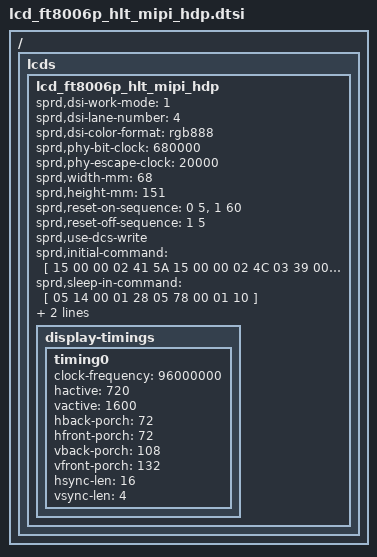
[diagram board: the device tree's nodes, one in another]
/ { lcds {
	lcd_ft8006p_hlt_mipi_hdp: lcd_ft8006p_hlt_mipi_hdp {

		sprd,dsi-work-mode = <1>; /* video burst mode*/
		sprd,dsi-lane-number = <4>;
		sprd,dsi-color-format = "rgb888";

		sprd,phy-bit-clock = <680000>;	/* kbps */
		sprd,phy-escape-clock = <20000>;/* kHz */

		sprd,width-mm = <68>;
		sprd,height-mm = <151>;

		sprd,reset-on-sequence = <0 5>, <1 60>;
		sprd,reset-off-sequence = <1 5>;

		sprd,use-dcs-write;

		sprd,initial-command = [
			/*------------  Display Initial Code Setting  ------------------------*/
			15 00 00 02 41 5A

			15 00 00 02 4C 03

			39 00 00 03 41 5A 03
			39 00 00 03 80 A9 00

			/*----------------------LCD initial code start----------------------*/
			/* Blank 9 */
			39 00 00 03 41 5A 09
			39 00 00 06 80 64 00 64 00 00
			/* Blank 10 */
			39 00 00 03 41 5A 0A
			39 00 00 11 80 A5 15 A5 AA A5 88 42 C8 8C 03 07 05 39 61 32 5A
			39 00 00 11 90 0C 0F 22 00 2A 18 64 00 88 03 03 EE EE 00 3F 2A
			39 00 00 11 A0 00 30 02 32 11 0D 60 01 FF FF 03 40 42 0F 94 11
			39 00 00 11 B0 E8 03 00 00 11 0D 60 00 FF FF 03 FF 34 0C 0F 0E
			39 00 00 0b C0 1F 03 00 08 20 34 00 00 00 00
			/* Blank 11 */
			39 00 00 03 41 5A 0B
			39 00 00 11 80 FF BE E6 00 00 04 10 1D 26 30 40 4D 51 5E 63 7A
			39 00 00 11 90 86 70 6F 62 5A 4C 3D 33 29 18 06 01 00 04 10 1D
			39 00 00 11 A0 26 30 40 4D 51 5E 63 7A 86 70 6F 62 5A 4C 3D 33
			39 00 00 06 B0 29 18 06 01 00
			/* Blank 12 */
			39 00 00 03 41 5A 0C
			39 00 00 11 80 00 00 20 42 00 00 80 05 54 00 00 00 20 42 00 00
			39 00 00 03 90 80 05
			/* Blank 13 */
			39 00 00 03 41 5A 0D
			39 00 00 11 80 7A D0 02 40 06 D7 00 FA 00 0A 0A 0A 0A 00 01 03
			39 00 00 11 90 00 00 00 00 AC A2 2A 00 00 00 AC A2 2A 57 31 00
			39 00 00 11 A0 00 00 00 00 00 AC A2 2A AA C2 2A AC A2 2A AA C2
			39 00 00 07 B0 2A 00 00 00 AA 52
			/* Blank 14 */
			39 00 00 03 41 5A 0E
			39 00 00 0d 80 F0 B1 71 EF 4B 20 37 0F AA AA 00 00
			/* Blank 15 */
			39 00 00 03 41 5A 0F
			39 00 00 0c 80 FF 00 55 55 23 88 88 1C 00 5A 5A
			/* Blank 16 */
			39 00 00 03 41 5A 10
			39 00 00 11 80 B5 45 09 18 01 3C 94 32 10 C4 C4 04 00 60 C0 00
			39 00 00 11 90 04 00 00 86 10 31 98 34 34 34 26 26 3E 1A 62 20
			39 00 00 05 A0 0C 40 00 8A
			/* Blank 17 */
			39 00 00 03 41 5A 11
			39 00 00 11 80 00 00 03 E7 1F 17 10 48 80 AA 90 1A 30 88 41 8A
			39 00 00 10 90 39 28 A9 C5 9A 7B F0 07 7E E0 07 7E 20 10 00
			/* Blank 18 */
			39 00 00 03 41 5A 12
			39 00 00 11 80 00 00 00 00 00 00 00 00 00 00 00 00 00 00 41 37
			39 00 00 11 90 2D 23 19 0F 05 FB F1 E7 00 00 00 00 00 00 00 00
			39 00 00 11 A0 00 00 00 00 00 00 00 00 00 00 00 00 00 00 00 00
			39 00 00 11 B0 00 00 00 00 00 00 00 00 00 2D 23 05 FB 00 2D 23
			39 00 00 05 C0 05 FB 00 01
			/* Blank 19 */
			39 00 00 03 41 5A 13
			39 00 00 11 80 FD 0F 00 0C 00 80 80 87 00 07 22 06 E7 B9 86 1A
			39 00 00 11 90 32 00 A2 2D 65 00 00 00 00 D0 C9 B7 FE 26 6F 32
			39 00 00 04 A0 22 90 04
			/* Blank 20 */
			39 00 00 03 41 5A 14
			39 00 00 11 80 01 02 40 5E D1 DF EF F7 FB FD 02 00 00 20 8B 0F
			39 00 00 11 90 D1 7B 40 6C 88 DE 03 E2 42 F4 1E 10 13 A2 F7 00
			39 00 00 11 A0 00 00 00 00 00 00 00 00 00 30 02 00 00 00 00 00
			39 00 00 11 B0 00 00 00 00 00 00 00 00 00 38 64 43 56 00 80 42
			39 00 00 11 C0 A1 F0 0E 44 EF 01 A5 38 DE 80 E8 3D A0 14 C7 0B
			39 00 00 11 D0 10 BD 07 94 E2 78 05 A2 F7 80 52 1C EF 42 F4 1E
			39 00 00 11 E0 50 8A E3 4D 88 DE 03 4A 71 BC 07 D1 7B 40 29 8E
			39 00 00 11 F0 B7 20 7A 0F 28 C5 31 02 7E BF 31 00 00 00 00 00
			/* Blank 21 */
			39 00 00 03 41 5A 15
			39 00 00 11 80 00 00 00 00 00 00 00 00 00 00 00 00 20 B0 C1 EF
			39 00 00 11 90 E7 01 42 F6 88 51 FB 0B 22 23 2B 62 D4 6A 83 C8
			39 00 00 11 A0 C8 00 00 00 00 00 00 00 00 00 00 00 00 00 00 21
			39 00 00 11 B0 33 62 D4 2A 00 00 00 00 26 00 E0 01 28 AD 09 9A
			39 00 00 11 C0 92 95 A6 82 A1 38 6D DB B6 6D DB B6 6D DB A6 A0
			39 00 00 11 D0 49 41 66 CA 20 04 D0 B6 6D DB B6 6D DB B6 AD 09
			39 00 00 11 E0 9A 10 95 A6 00 81 30 6D DB B6 6D DB B6 6D DB A6
			39 00 00 11 F0 A0 69 49 66 EA 28 86 D0 B6 6D DB B6 6D DB B6 00
			/* Blank 22 */
			39 00 00 03 41 5A 16
			39 00 00 11 80 00 00 00 00 00 00 00 00 00 00 00 00 00 00 00 00
			39 00 00 0b 90 00 00 00 00 80 42 2B 01 00 00
			/* Blank 24 */
			39 00 00 03 41 5A 18
			39 00 00 11 80 EF BD F7 DE 7B EF BD 07 08 08 0A 0C 0C 0C 0C 0C
			39 00 00 11 90 0C 0C 0C 5C 09 A8 AA AA AA AA AA AA AA AA AA 5A
			39 00 00 11 A0 59 59 59 59 59 59 59 59 59 59 59 09 04 FF 00 80
			39 00 00 10 B0 80 00 04 20 00 01 08 40 00 02 10 80 00 04 00
			/* Blank 25 */
			39 00 00 03 41 5A 19
			39 00 00 11 80 F0 D9 C8 BA AF A6 9E 98 92 8D 88 84 00 60 F6 CF
			39 00 00 11 90 FC 6F F6 EF CF AF 0F FF AF B5 71 0E 6C 4A 69 08
			39 00 00 05 A0 00 00 48 00
			/* Blank 26 */
			39 00 00 03 41 5A 1A
			39 00 00 11 80 FF 04 04 08 0C 00 10 14 18 1C 00 20 28 30 38 00
			39 00 00 11 90 40 48 50 58 00 60 68 70 78 00 80 88 90 98 00 A0
			39 00 00 11 A0 A8 B0 B8 00 C0 C8 D0 D8 00 E0 E8 F0 F8 00 FC FE
			39 00 00 11 B0 FF 00 00 04 08 0C 00 10 14 18 1C 00 20 28 30 38
			39 00 00 11 C0 00 40 48 50 58 00 60 68 70 78 00 80 88 90 98 00
			39 00 00 11 D0 A0 A8 B0 B8 00 C0 C8 D0 D8 00 E0 E8 F0 F8 00 FC
			39 00 00 11 E0 FE FF 00 00 04 08 0C 00 10 14 18 1C 00 20 28 30
			39 00 00 11 F0 38 00 40 48 50 58 00 60 68 70 78 00 80 88 90 98
			/* Blank 27 */
			39 00 00 03 41 5A 1B
			39 00 00 11 80 00 A0 A8 B0 B8 00 C0 C8 D0 D8 00 E0 E8 F0 F8 00
			39 00 00 06 90 FC FE FF 00 00
			/* Blank 28 */
			39 00 00 03 41 5A 1C
			39 00 00 11 80 33 22 00 03 5A 02 5A 54 E5 FF C7 00 18 28 18 08
			39 00 00 11 90 10 0C 07 09 06 06 0A 10 0C 09 0B 06 06 F0 78 40
			39 00 00 11 A0 20 08 08 06 13 C0 34 1E 0A 08 66 D1 A0 1C 20 20
			39 00 00 11 B0 18 04 20 00 C0 04 28 01 4C 00 23 18 10 0A 06 C9
			39 00 00 11 C0 04 70 41 58 54 B5 4A 55 15 00 78 F8 99 99 99 99
			39 00 00 11 D0 99 19 11 11 11 11 11 11 08 C8 E3 81 00 20 80 27
			39 00 00 11 E0 E2 89 00 00 00 00 40 00 00 31 04 41 B6 6D DB B6
			39 00 00 11 F0 6D DB B6 6D DB B6 6D DB B6 6D DB B6 6D C0 03 40
			/* Blank 29 */
			39 00 00 03 41 5A 1D
			39 00 00 11 80 00 01 54 0B 23 18 00 00 80 00 00 00 00 00 00 00
			/* Blank 34 */
			39 00 00 03 41 5A 22
			39 00 00 10 80 00 5E 00 00 00 00 00 00 5E 00 00 00 00 00 00
			/* Blank 36 */
			39 00 00 03 41 5A 24
			39 00 00 11 80 2D D3 00 55 55 55 55 55 55 55 55 1F 00 AA 3E 00
			39 00 00 05 90 00 00 00 00
			/* Blank 37 */
			39 00 00 03 41 5A 25
			39 00 00 11 80 01 05 00 05 00 00 00 00 00 00 00 00 00 00 00 FF
			39 00 00 0c 90 0F 00 00 24 00 00 00 00 FF 07 35
			/* Blank 38 */
			39 00 00 03 41 5A 26
			39 00 00 11 80 00 83 00 FF FF 60 00 01 00 00 00 00 00 00 2F 44
			39 00 00 04 90 5A A5 5A

			/*----------------------LCD initial code End----------------------*/

			/* SPI FINISH */
			15 00 00 02 90 A5
			39 00 00 03 41 00 2F

			05 78 00 01 29
			05 14 00 01 11
			/*-------------  Display Initial Setting end -------------------------*/
		];

		sprd,sleep-in-command = [
			05 14 00 01 28
			05 78 00 01 10
		];

		sprd,sleep-out-command = [
			05 78 00 01 11
			05 14 00 01 29
		];

		display-timings {
			timing0 {
				clock-frequency = <96000000>;
				hactive = <720>;
				vactive = <1600>;
				hback-porch = <72>;
				hfront-porch = <72>;
				vback-porch = <108>;
				vfront-porch = <132>;
				hsync-len = <16>;
				vsync-len = <4>;
			};
		};
	};
};};
